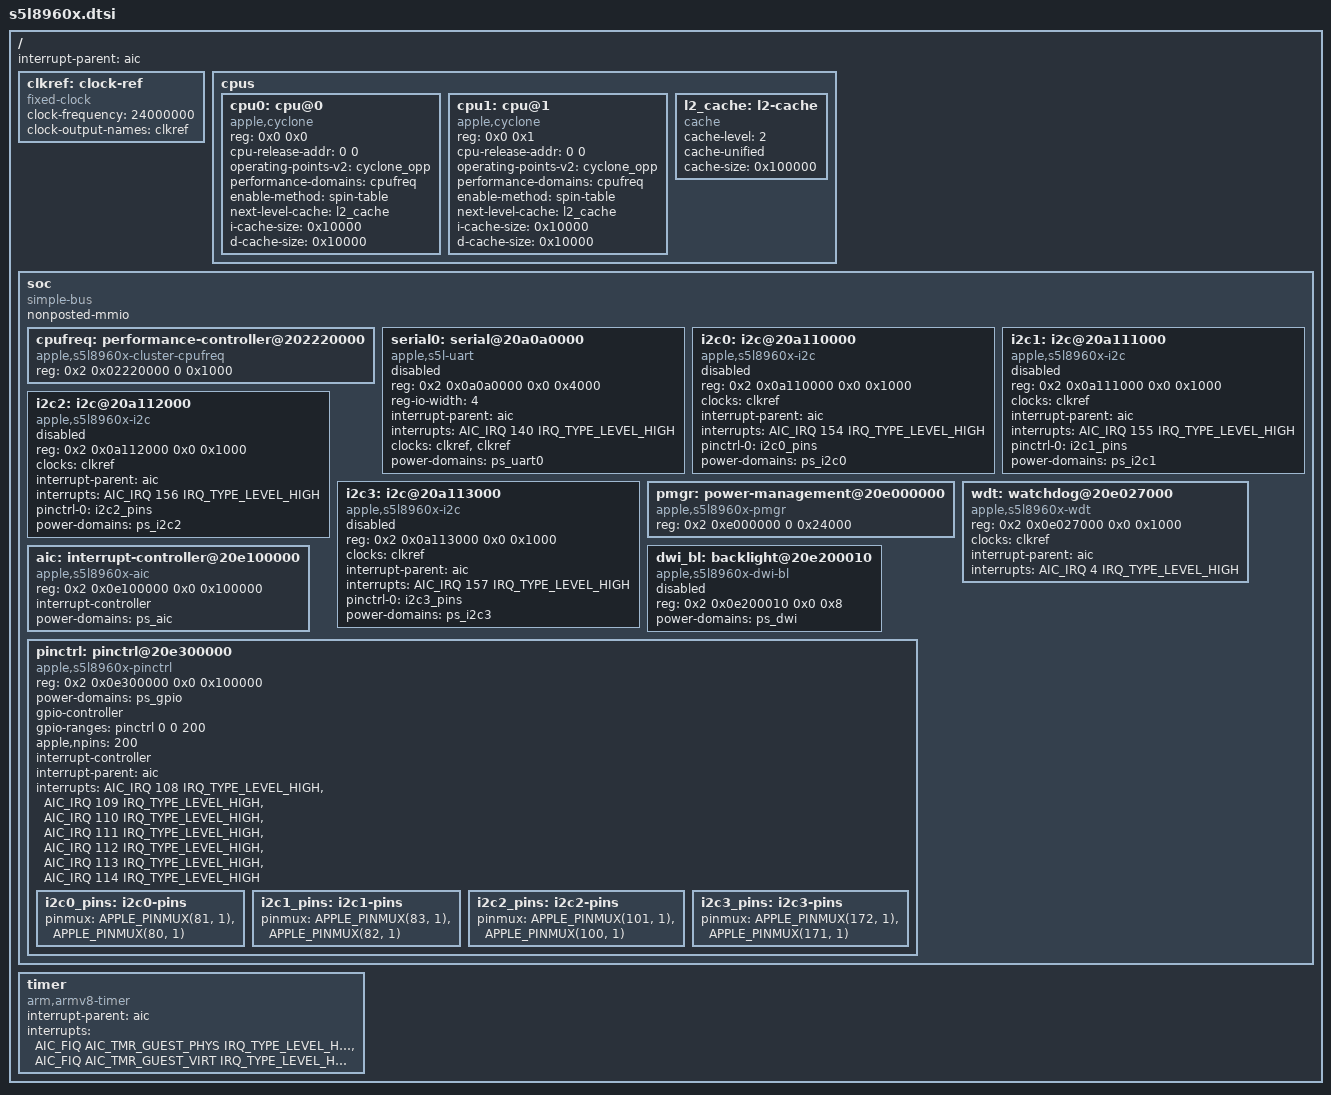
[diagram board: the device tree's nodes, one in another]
// SPDX-License-Identifier: GPL-2.0+ OR MIT
/*
 * Apple S5L8960X "A7" SoC
 *
 * Other Names: H6, "Alcatraz"
 *
 * Copyright (c) 2022, Konrad Dybcio <konradybcio@kernel.org>
 * Based on Asahi Linux's M1 (t8103.dtsi) and Corellium's A10 efforts.
 */

#include <dt-bindings/gpio/gpio.h>
#include <dt-bindings/interrupt-controller/apple-aic.h>
#include <dt-bindings/interrupt-controller/irq.h>
#include <dt-bindings/pinctrl/apple.h>

/ {
	interrupt-parent = <&aic>;
	#address-cells = <2>;
	#size-cells = <2>;

	clkref: clock-ref {
		compatible = "fixed-clock";
		#clock-cells = <0>;
		clock-frequency = <24000000>;
		clock-output-names = "clkref";
	};

	cpus {
		#address-cells = <2>;
		#size-cells = <0>;

		cpu0: cpu@0 {
			compatible = "apple,cyclone";
			reg = <0x0 0x0>;
			cpu-release-addr = <0 0>; /* To be filled by loader */
			operating-points-v2 = <&cyclone_opp>;
			performance-domains = <&cpufreq>;
			enable-method = "spin-table";
			device_type = "cpu";
			next-level-cache = <&l2_cache>;
			i-cache-size = <0x10000>;
			d-cache-size = <0x10000>;
		};

		cpu1: cpu@1 {
			compatible = "apple,cyclone";
			reg = <0x0 0x1>;
			cpu-release-addr = <0 0>; /* To be filled by loader */
			operating-points-v2 = <&cyclone_opp>;
			performance-domains = <&cpufreq>;
			enable-method = "spin-table";
			device_type = "cpu";
			next-level-cache = <&l2_cache>;
			i-cache-size = <0x10000>;
			d-cache-size = <0x10000>;
		};

		l2_cache: l2-cache {
			compatible = "cache";
			cache-level = <2>;
			cache-unified;
			cache-size = <0x100000>;
		};
	};

	soc {
		compatible = "simple-bus";
		#address-cells = <2>;
		#size-cells = <2>;
		nonposted-mmio;
		ranges;

		cpufreq: performance-controller@202220000 {
			compatible = "apple,s5l8960x-cluster-cpufreq";
			reg = <0x2 0x02220000 0 0x1000>;
			#performance-domain-cells = <0>;
		};

		serial0: serial@20a0a0000 {
			compatible = "apple,s5l-uart";
			reg = <0x2 0x0a0a0000 0x0 0x4000>;
			reg-io-width = <4>;
			interrupt-parent = <&aic>;
			interrupts = <AIC_IRQ 140 IRQ_TYPE_LEVEL_HIGH>;
			/* Use the bootloader-enabled clocks for now. */
			clocks = <&clkref>, <&clkref>;
			clock-names = "uart", "clk_uart_baud0";
			power-domains = <&ps_uart0>;
			status = "disabled";
		};

		i2c0: i2c@20a110000 {
			compatible = "apple,s5l8960x-i2c", "apple,i2c";
			reg = <0x2 0x0a110000 0x0 0x1000>;
			clocks = <&clkref>;
			interrupt-parent = <&aic>;
			interrupts = <AIC_IRQ 154 IRQ_TYPE_LEVEL_HIGH>;
			pinctrl-0 = <&i2c0_pins>;
			pinctrl-names = "default";
			power-domains = <&ps_i2c0>;
			#address-cells = <1>;
			#size-cells = <0>;
			status = "disabled";
		};

		i2c1: i2c@20a111000 {
			compatible = "apple,s5l8960x-i2c", "apple,i2c";
			reg = <0x2 0x0a111000 0x0 0x1000>;
			clocks = <&clkref>;
			interrupt-parent = <&aic>;
			interrupts = <AIC_IRQ 155 IRQ_TYPE_LEVEL_HIGH>;
			pinctrl-0 = <&i2c1_pins>;
			pinctrl-names = "default";
			power-domains = <&ps_i2c1>;
			#address-cells = <1>;
			#size-cells = <0>;
			status = "disabled";
		};

		i2c2: i2c@20a112000 {
			compatible = "apple,s5l8960x-i2c", "apple,i2c";
			reg = <0x2 0x0a112000 0x0 0x1000>;
			clocks = <&clkref>;
			interrupt-parent = <&aic>;
			interrupts = <AIC_IRQ 156 IRQ_TYPE_LEVEL_HIGH>;
			pinctrl-0 = <&i2c2_pins>;
			pinctrl-names = "default";
			power-domains = <&ps_i2c2>;
			#address-cells = <1>;
			#size-cells = <0>;
			status = "disabled";
		};

		i2c3: i2c@20a113000 {
			compatible = "apple,s5l8960x-i2c", "apple,i2c";
			reg = <0x2 0x0a113000 0x0 0x1000>;
			clocks = <&clkref>;
			interrupt-parent = <&aic>;
			interrupts = <AIC_IRQ 157 IRQ_TYPE_LEVEL_HIGH>;
			pinctrl-0 = <&i2c3_pins>;
			pinctrl-names = "default";
			power-domains = <&ps_i2c3>;
			#address-cells = <1>;
			#size-cells = <0>;
			status = "disabled";
		};

		pmgr: power-management@20e000000 {
			compatible = "apple,s5l8960x-pmgr", "apple,pmgr", "syscon", "simple-mfd";
			#address-cells = <1>;
			#size-cells = <1>;

			reg = <0x2 0xe000000 0 0x24000>;
		};

		wdt: watchdog@20e027000 {
			compatible = "apple,s5l8960x-wdt", "apple,wdt";
			reg = <0x2 0x0e027000 0x0 0x1000>;
			clocks = <&clkref>;
			interrupt-parent = <&aic>;
			interrupts = <AIC_IRQ 4 IRQ_TYPE_LEVEL_HIGH>;
		};

		aic: interrupt-controller@20e100000 {
			compatible = "apple,s5l8960x-aic", "apple,aic";
			reg = <0x2 0x0e100000 0x0 0x100000>;
			#interrupt-cells = <3>;
			interrupt-controller;
			power-domains = <&ps_aic>;
		};

		dwi_bl: backlight@20e200010 {
			compatible = "apple,s5l8960x-dwi-bl", "apple,dwi-bl";
			reg = <0x2 0x0e200010 0x0 0x8>;
			power-domains = <&ps_dwi>;
			status = "disabled";
		};

		pinctrl: pinctrl@20e300000 {
			compatible = "apple,s5l8960x-pinctrl", "apple,pinctrl";
			reg = <0x2 0x0e300000 0x0 0x100000>;
			power-domains = <&ps_gpio>;

			gpio-controller;
			#gpio-cells = <2>;
			gpio-ranges = <&pinctrl 0 0 200>;
			apple,npins = <200>;

			interrupt-controller;
			#interrupt-cells = <2>;
			interrupt-parent = <&aic>;
			interrupts = <AIC_IRQ 108 IRQ_TYPE_LEVEL_HIGH>,
				     <AIC_IRQ 109 IRQ_TYPE_LEVEL_HIGH>,
				     <AIC_IRQ 110 IRQ_TYPE_LEVEL_HIGH>,
				     <AIC_IRQ 111 IRQ_TYPE_LEVEL_HIGH>,
				     <AIC_IRQ 112 IRQ_TYPE_LEVEL_HIGH>,
				     <AIC_IRQ 113 IRQ_TYPE_LEVEL_HIGH>,
				     <AIC_IRQ 114 IRQ_TYPE_LEVEL_HIGH>;

			i2c0_pins: i2c0-pins {
				pinmux = <APPLE_PINMUX(81, 1)>,
					 <APPLE_PINMUX(80, 1)>;
			};

			i2c1_pins: i2c1-pins {
				pinmux = <APPLE_PINMUX(83, 1)>,
					 <APPLE_PINMUX(82, 1)>;
			};

			i2c2_pins: i2c2-pins {
				pinmux = <APPLE_PINMUX(101, 1)>,
					 <APPLE_PINMUX(100, 1)>;
			};

			i2c3_pins: i2c3-pins {
				pinmux = <APPLE_PINMUX(172, 1)>,
					 <APPLE_PINMUX(171, 1)>;
			};
		};
	};

	timer {
		compatible = "arm,armv8-timer";
		interrupt-parent = <&aic>;
		interrupt-names = "phys", "virt";
		/* Note that A7 doesn't actually have a hypervisor (EL2 is not implemented). */
		interrupts = <AIC_FIQ AIC_TMR_GUEST_PHYS IRQ_TYPE_LEVEL_HIGH>,
			     <AIC_FIQ AIC_TMR_GUEST_VIRT IRQ_TYPE_LEVEL_HIGH>;
	};
};

#include "s5l8960x-pmgr.dtsi"
